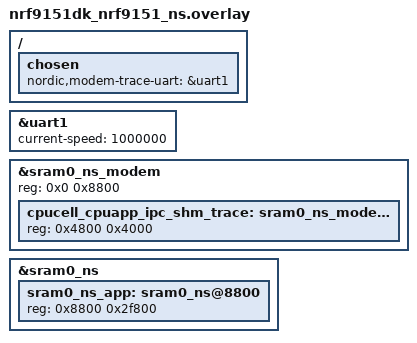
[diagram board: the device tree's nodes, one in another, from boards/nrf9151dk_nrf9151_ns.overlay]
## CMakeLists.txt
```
#
# Copyright (c) 2023 Nordic Semiconductor
#
# SPDX-License-Identifier: LicenseRef-Nordic-5-Clause
#

cmake_minimum_required(VERSION 3.20.0)

find_package(Zephyr REQUIRED HINTS $ENV{ZEPHYR_BASE})
project(udp)

# NORDIC SDK APP START
target_sources(app PRIVATE src/main.c)
# NORDIC SDK APP END

zephyr_include_directories(src)
```

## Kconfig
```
#
# Copyright (c) 2023 Nordic Semiconductor ASA
#
# SPDX-License-Identifier: LicenseRef-Nordic-5-Clause
#

menu "UDP sample settings"

config UDP_SAMPLE_DATA_UPLOAD_SIZE_BYTES
	int "Number of bytes transmitted to the server"
	default 10

config UDP_SAMPLE_DATA_UPLOAD_FREQUENCY_SECONDS
	int "How often data is transmitted to the server"
	default 900

config UDP_SAMPLE_SERVER_ADDRESS_STATIC
	string "UDP server IP address"
	default "8.8.8.8"

config UDP_SAMPLE_SERVER_PORT
	int "UDP server port number"
	default "2469"

endmenu

module = UDP_SAMPLE
module-str = UDP sample
source "$(ZEPHYR_BASE)/subsys/logging/Kconfig.template.log_config"

menu "Zephyr Kernel"
source "Kconfig.zephyr"
endmenu
```

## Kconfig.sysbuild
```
#
# Copyright (c) 2024 Nordic Semiconductor ASA
#
# SPDX-License-Identifier: LicenseRef-Nordic-5-Clause
#

config WIFI_NRF70
	default y if BOARD_NRF7002DK_NRF5340_CPUAPP_NS || \
		BOARD_NRF5340DK_NRF5340_CPUAPP_NS || \
		BOARD_NRF54L15DK_NRF54L15_CPUAPP || \
		BOARD_NRF54H20DK_NRF54H20_CPUAPP || \
		BOARD_NRF54LM20DK_NRF54LM20A_CPUAPP || \
		BOARD_NRF54LM20DK_NRF54LM20B_CPUAPP

config PARTITION_MANAGER
	default n

source "share/sysbuild/Kconfig"
```

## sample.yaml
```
sample:
  name: UDP sample
tests:
  sample.net.udp:
    sysbuild: true
    build_only: true
    integration_platforms:
      - nrf9151dk/nrf9151/ns
    platform_allow:
      - nrf9151dk/nrf9151/ns
    tags:
      - ci_build
      - sysbuild
      - ci_samples_net
  sample.net.udp.emulation:
    sysbuild: true
    build_only: true
    integration_platforms:
      - native_sim
    platform_allow:
      - native_sim
    tags:
      - ci_build
      - sysbuild
      - ci_samples_net
  sample.net.udp.wifi:
    sysbuild: true
    build_only: true
    integration_platforms:
      - nrf7002dk/nrf5340/cpuapp/ns
      - nrf7120dk/nrf7120/cpuapp/ns
    platform_allow:
      - nrf7002dk/nrf5340/cpuapp/ns
      - nrf7120dk/nrf7120/cpuapp/ns
    tags:
      - ci_build
      - sysbuild
      - ci_samples_net
    extra_args:
      - udp_EXTRA_CONF_FILE="wifi.conf"
  sample.net.udp.nrf7002eb_interposer.wifi:
    sysbuild: true
    build_only: true
    integration_platforms:
      - nrf54h20dk/nrf54h20/cpuapp
    platform_allow:
      - nrf54h20dk/nrf54h20/cpuapp
    tags:
      - ci_build
      - sysbuild
      - ci_samples_net
    extra_args:
      - udp_SHIELD="nrf7002eb_interposer_p1;nrf7002eb"
      - udp_SNIPPET="nrf70-wifi;wifi-credentials"
      - udp_EXTRA_CONF_FILE="wifi.conf"
  sample.net.udp.nrf54l15_nrf7002eb2.wifi:
    sysbuild: true
    build_only: true
    integration_platforms:
      - nrf54l15dk/nrf54l15/cpuapp
    platform_allow:
      - nrf54l15dk/nrf54l15/cpuapp
    tags:
      - ci_build
      - sysbuild
      - ci_samples_net
    extra_args:
      - udp_SHIELD="nrf7002eb2"
      - udp_SNIPPET="nrf70-wifi;wifi-credentials"
      - udp_EXTRA_CONF_FILE="wifi.conf"
  sample.net.udp.nrf54lm20_nrf7002eb2.wifi:
    sysbuild: true
    build_only: true
    integration_platforms:
      - nrf54lm20dk/nrf54lm20a/cpuapp
      - nrf54lm20dk/nrf54lm20b/cpuapp
    platform_allow:
      - nrf54lm20dk/nrf54lm20a/cpuapp
      - nrf54lm20dk/nrf54lm20b/cpuapp
    tags:
      - ci_build
      - sysbuild
      - ci_samples_net
    extra_args:
      - udp_SHIELD="nrf7002eb2"
      - udp_SNIPPET=wifi-credentials
      - udp_EXTRA_CONF_FILE="wifi.conf"
```

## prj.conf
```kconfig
#
# Copyright (c) 2023 Nordic Semiconductor ASA
#
# SPDX-License-Identifier: LicenseRef-Nordic-5-Clause
#

# General configurations
CONFIG_LOG=y

# Network
CONFIG_NETWORKING=y
CONFIG_NET_NATIVE=y
CONFIG_NET_IPV4=y
CONFIG_NET_IPV6=y
CONFIG_NET_SOCKETS=y
CONFIG_POSIX_API=y
CONFIG_NET_CONNECTION_MANAGER=y

# Heap and stacks
CONFIG_HEAP_MEM_POOL_SIZE=1280
CONFIG_MAIN_STACK_SIZE=4096
CONFIG_SYSTEM_WORKQUEUE_STACK_SIZE=2048
```

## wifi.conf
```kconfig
#
# Copyright (c) 2026 Nordic Semiconductor ASA
#
# SPDX-License-Identifier: LicenseRef-Nordic-5-Clause
#

# Common Wi-Fi + networking configuration shared by all Wi-Fi builds of
# this sample (nRF70 and nRF71).

# Logging
CONFIG_NET_LOG=y

# Wi-Fi stack
CONFIG_WIFI=y
CONFIG_WIFI_NM_WPA_SUPPLICANT=y
CONFIG_WIFI_NM_WPA_SUPPLICANT_LOG_LEVEL_INF=y
CONFIG_NET_L2_ETHERNET=y

# Wi-Fi credentials. TF-M (_ns) builds use PSA Protected Storage. Non-TF-M
# builds use the Settings subsystem, requiring the wifi-credentials snippet.
CONFIG_WIFI_CREDENTIALS=y

# Connection Manager Wi-Fi connectivity layer (sdk-nrf).
CONFIG_L2_WIFI_CONNECTIVITY=y
CONFIG_L2_WIFI_CONNECTIVITY_AUTO_CONNECT=n
CONFIG_L2_WIFI_CONNECTIVITY_AUTO_DOWN=n

# Networking
CONFIG_NET_SOCKETS=y
CONFIG_NET_SOCKETS_OFFLOAD=n
CONFIG_NET_IPV6=y
CONFIG_NET_UDP=y
CONFIG_NET_TCP=y
CONFIG_NET_DHCPV4=y
# Run DHCPv6 on RA, covering both stateful and stateless configurations
CONFIG_NET_DHCPV6=y
CONFIG_NET_DHCPV6_START_ON_RA=y
CONFIG_NET_CONTEXT_SNDTIMEO=y
CONFIG_NET_CONTEXT_RCVTIMEO=y

# DNS
CONFIG_DNS_RESOLVER=y
CONFIG_NET_SOCKETS_DNS_TIMEOUT=30000

# Wi-Fi shell
CONFIG_SHELL=y
CONFIG_SHELL_CMDS_RESIZE=n
CONFIG_NET_L2_WIFI_SHELL=y

# POSIX
CONFIG_POSIX_NETWORKING=y
CONFIG_POSIX_FD_MGMT=n
CONFIG_POSIX_MESSAGE_PASSING=n
CONFIG_POSIX_THREAD_THREADS_MAX=0

# Network resource sizing (workload-specific for this sample)
CONFIG_NET_MAX_CONN=8
CONFIG_NET_MAX_CONTEXTS=6
CONFIG_ZVFS_POLL_MAX=8
CONFIG_NET_PKT_TX_COUNT=6
CONFIG_NET_PKT_RX_COUNT=6
CONFIG_NET_BUF_TX_COUNT=12
CONFIG_NET_BUF_RX_COUNT=6
CONFIG_NET_PKT_BUF_RX_DATA_POOL_SIZE=4096
CONFIG_NET_PKT_BUF_TX_DATA_POOL_SIZE=4096

# Floating-point printf support (Wi-Fi shell prints PHY TX rate as %f)
CONFIG_CBPRINTF_FP_SUPPORT=y

# Stack sizes
CONFIG_MAIN_STACK_SIZE=6144
CONFIG_SHELL_STACK_SIZE=6144
CONFIG_NET_RX_STACK_SIZE=4096

# Heap sizes
CONFIG_HEAP_MEM_POOL_IGNORE_MIN=y
CONFIG_HEAP_MEM_POOL_SIZE=37000
CONFIG_NRF_WIFI_DATA_HEAP_SIZE=65536
```

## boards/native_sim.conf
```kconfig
#
# Copyright (c) 2023 Nordic Semiconductor ASA
#
# SPDX-License-Identifier: LicenseRef-Nordic-5-Clause
#

# Networking config
CONFIG_NET_TCP=y
CONFIG_NET_UDP=y
CONFIG_NET_SOCKETS=y
CONFIG_POSIX_API=y
CONFIG_MBEDTLS_CIPHERSUITE_TLS_ECDHE_RSA_WITH_AES_128_CBC_SHA256=y
CONFIG_NET_SOCKETS_SOCKOPT_TLS=y
CONFIG_NET_PKT_RX_COUNT=32
CONFIG_NET_PKT_TX_COUNT=32
CONFIG_NET_BUF_RX_COUNT=32
CONFIG_NET_BUF_TX_COUNT=32
CONFIG_NET_IF_UNICAST_IPV6_ADDR_COUNT=3
CONFIG_NET_IF_MCAST_IPV6_ADDR_COUNT=4
CONFIG_NET_MAX_CONTEXTS=10
CONFIG_NET_L2_ETHERNET=y
CONFIG_NET_CONTEXT_SNDTIMEO=y

CONFIG_ETH_NATIVE_TAP=y

# Network driver config
CONFIG_TEST_RANDOM_GENERATOR=y

# DNS
CONFIG_DNS_RESOLVER=y
CONFIG_DNS_SERVER_IP_ADDRESSES=y
CONFIG_DNS_SERVER1="8.8.8.8"
CONFIG_DNS_RESOLVER_MAX_SERVERS=2

# Network address config
CONFIG_NET_CONFIG_SETTINGS=y
CONFIG_NET_CONFIG_NEED_IPV4=y
CONFIG_NET_CONFIG_MY_IPV4_ADDR="192.0.2.1"
CONFIG_NET_CONFIG_MY_IPV4_GW="192.0.2.2"
```

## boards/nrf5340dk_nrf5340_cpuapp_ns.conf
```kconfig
#
# Copyright (c) 2025 Nordic Semiconductor ASA
#
# SPDX-License-Identifier: LicenseRef-Nordic-5-Clause
#

# General
CONFIG_POSIX_TIMERS=y
CONFIG_HEAP_MEM_POOL_SIZE=40144
CONFIG_NRF_WIFI_CTRL_HEAP_SIZE=15000
CONFIG_NRF_WIFI_DATA_HEAP_SIZE=64856
CONFIG_HEAP_MEM_POOL_IGNORE_MIN=y
CONFIG_MAIN_STACK_SIZE=6144

# Wi-Fi
CONFIG_WIFI=y
CONFIG_WIFI_NRF70=y
CONFIG_WIFI_CREDENTIALS=y

# Optimize Wi-Fi stack to save some memory
CONFIG_NRF70_RX_NUM_BUFS=16
CONFIG_NRF70_MAX_TX_AGGREGATION=4

# Shell
CONFIG_SHELL=y
CONFIG_SHELL_STACK_SIZE=6144
CONFIG_NET_L2_WIFI_SHELL=y

# WPA
CONFIG_WIFI_NM_WPA_SUPPLICANT=y

# NET sockets
CONFIG_NET_L2_ETHERNET=y
CONFIG_NET_UDP=y
CONFIG_NET_DHCPV4=y

# DNS
CONFIG_DNS_RESOLVER=y
CONFIG_NET_SOCKETS_DNS_TIMEOUT=30000

# Zephyr NET Connection Manager Connectivity layer.
CONFIG_L2_WIFI_CONNECTIVITY=y
CONFIG_L2_WIFI_CONNECTIVITY_AUTO_CONNECT=n
CONFIG_L2_WIFI_CONNECTIVITY_AUTO_DOWN=n

# Optimize TF-M
CONFIG_TFM_PROFILE_TYPE_SMALL=y

# Floating-point printf support
CONFIG_CBPRINTF_FP_SUPPORT=y
```

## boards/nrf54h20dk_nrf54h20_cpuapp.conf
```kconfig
#
# Copyright (c) 2024 Nordic Semiconductor ASA
#
# SPDX-License-Identifier: LicenseRef-Nordic-5-Clause
#

# Logging
CONFIG_LOG=y
CONFIG_LOG_MODE_IMMEDIATE=y

# Wi-Fi
CONFIG_WIFI=y
CONFIG_WIFI_NRF70=y
CONFIG_WIFI_CREDENTIALS=y
# Needed for Wi-Fi credentials
CONFIG_FLASH=y
CONFIG_FLASH_PAGE_LAYOUT=y
CONFIG_FLASH_MAP=y
CONFIG_ZMS=y
CONFIG_SETTINGS=y

# WPA supplicant
CONFIG_WIFI_NM_WPA_SUPPLICANT=y
CONFIG_WIFI_NM_WPA_SUPPLICANT_LOG_LEVEL_INF=y

# Networking
CONFIG_NET_L2_ETHERNET=y
CONFIG_NET_SOCKETS=y
CONFIG_NET_IPV6=y
CONFIG_NET_UDP=y
CONFIG_NET_TCP=y
CONFIG_NET_DHCPV4=y
CONFIG_DNS_RESOLVER=y
CONFIG_DNS_RESOLVER_AI_MAX_ENTRIES=4

# NET sockets
CONFIG_NET_UDP=y
CONFIG_NET_TCP=y
CONFIG_NET_MAX_CONN=6
CONFIG_NET_MAX_CONTEXTS=5
CONFIG_ZVFS_POLL_MAX=8
CONFIG_NET_SOCKETS_OFFLOAD=n
CONFIG_NET_DHCPV4=y
CONFIG_NET_CONTEXT_SNDTIMEO=y
CONFIG_NET_CONTEXT_RCVTIMEO=y
CONFIG_NET_MAX_CONTEXTS=3

# NET buffers
CONFIG_NET_PKT_TX_COUNT=6
CONFIG_NET_PKT_RX_COUNT=6
CONFIG_NET_BUF_TX_COUNT=12
CONFIG_NET_BUF_RX_COUNT=6
CONFIG_NRF70_RX_NUM_BUFS=6
CONFIG_NET_PKT_BUF_RX_DATA_POOL_SIZE=4096
CONFIG_NET_PKT_BUF_TX_DATA_POOL_SIZE=4096
CONFIG_NRF70_MAX_TX_AGGREGATION=1

# Kernel options
CONFIG_POSIX_NETWORKING=y
CONFIG_ZVFS_OPEN_MAX=21

# Shell
CONFIG_SHELL=y
CONFIG_SHELL_CMDS_RESIZE=n
CONFIG_NET_L2_WIFI_SHELL=y

# Zephyr NET Connection Manager Connectivity layer.
CONFIG_L2_WIFI_CONNECTIVITY=y
CONFIG_L2_WIFI_CONNECTIVITY_AUTO_CONNECT=y
CONFIG_L2_WIFI_CONNECTIVITY_AUTO_DOWN=n

# Stack sizes
CONFIG_MAIN_STACK_SIZE=6144
CONFIG_NET_TX_STACK_SIZE=2048
CONFIG_NET_RX_STACK_SIZE=2048
CONFIG_NET_MGMT_EVENT_STACK_SIZE=4096
CONFIG_SYSTEM_WORKQUEUE_STACK_SIZE=3100
CONFIG_NRF70_IRQ_WQ_STACK_SIZE=1024
CONFIG_NRF70_BH_WQ_STACK_SIZE=2300
CONFIG_SHELL_STACK_SIZE=4400
CONFIG_ISR_STACK_SIZE=512

# Heap sizes
CONFIG_HEAP_MEM_POOL_IGNORE_MIN=y
CONFIG_HEAP_MEM_POOL_SIZE=32000
CONFIG_NRF_WIFI_CTRL_HEAP_SIZE=15000
CONFIG_NRF_WIFI_DATA_HEAP_SIZE=40000
# POSIX API memory optimizations
CONFIG_POSIX_FD_MGMT=n
CONFIG_POSIX_MESSAGE_PASSING=n
CONFIG_POSIX_THREAD_THREADS_MAX=0

# Floating-point printf support
CONFIG_CBPRINTF_FP_SUPPORT=y
```

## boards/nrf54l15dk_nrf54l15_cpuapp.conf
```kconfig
#
# Copyright (c) 2024 Nordic Semiconductor ASA
#
# SPDX-License-Identifier: LicenseRef-Nordic-5-Clause
#

# Logging
CONFIG_LOG=y
CONFIG_LOG_MODE_IMMEDIATE=y

# Wi-Fi
CONFIG_WIFI=y
CONFIG_WIFI_NRF70=y
CONFIG_WIFI_CREDENTIALS=y
# Needed for Wi-Fi credentials
CONFIG_FLASH=y
CONFIG_FLASH_PAGE_LAYOUT=y
CONFIG_FLASH_MAP=y
CONFIG_ZMS=y
CONFIG_SETTINGS=y

# WPA supplicant
CONFIG_WIFI_NM_WPA_SUPPLICANT=y
CONFIG_WIFI_NM_WPA_SUPPLICANT_LOG_LEVEL_INF=y

# Networking
CONFIG_NET_L2_ETHERNET=y
CONFIG_NET_SOCKETS=y
CONFIG_NET_IPV6=y
CONFIG_NET_UDP=y
CONFIG_NET_TCP=y
CONFIG_NET_DHCPV4=y
CONFIG_DNS_RESOLVER=y
CONFIG_DNS_RESOLVER_AI_MAX_ENTRIES=4

# NET sockets
CONFIG_NET_UDP=y
CONFIG_NET_TCP=y
CONFIG_NET_MAX_CONN=6
CONFIG_NET_MAX_CONTEXTS=5
CONFIG_ZVFS_POLL_MAX=8
CONFIG_NET_SOCKETS_OFFLOAD=n
CONFIG_NET_DHCPV4=y
CONFIG_NET_CONTEXT_SNDTIMEO=y
CONFIG_NET_CONTEXT_RCVTIMEO=y
CONFIG_NET_MAX_CONTEXTS=3

# NET buffers
CONFIG_NET_PKT_TX_COUNT=6
CONFIG_NET_PKT_RX_COUNT=6
CONFIG_NET_BUF_TX_COUNT=12
CONFIG_NET_BUF_RX_COUNT=6
CONFIG_NRF70_RX_NUM_BUFS=6
CONFIG_NET_PKT_BUF_RX_DATA_POOL_SIZE=4096
CONFIG_NET_PKT_BUF_TX_DATA_POOL_SIZE=4096
CONFIG_NRF70_MAX_TX_AGGREGATION=1

# Kernel options
CONFIG_POSIX_NETWORKING=y

# Shell
CONFIG_SHELL=y
CONFIG_SHELL_CMDS_RESIZE=n
CONFIG_NET_L2_WIFI_SHELL=y

# Zephyr NET Connection Manager Connectivity layer.
CONFIG_L2_WIFI_CONNECTIVITY=y
CONFIG_L2_WIFI_CONNECTIVITY_AUTO_CONNECT=y
CONFIG_L2_WIFI_CONNECTIVITY_AUTO_DOWN=n

# Stack sizes
CONFIG_MAIN_STACK_SIZE=6144
CONFIG_NET_TX_STACK_SIZE=2048
CONFIG_NET_RX_STACK_SIZE=2048
CONFIG_NET_MGMT_EVENT_STACK_SIZE=4096
CONFIG_SYSTEM_WORKQUEUE_STACK_SIZE=3100
CONFIG_NRF70_IRQ_WQ_STACK_SIZE=1024
CONFIG_NRF70_BH_WQ_STACK_SIZE=2300
CONFIG_SHELL_STACK_SIZE=4400
CONFIG_ISR_STACK_SIZE=512

# Heap sizes
CONFIG_HEAP_MEM_POOL_IGNORE_MIN=y
CONFIG_HEAP_MEM_POOL_SIZE=32000
CONFIG_NRF_WIFI_CTRL_HEAP_SIZE=15000
CONFIG_NRF_WIFI_DATA_HEAP_SIZE=40000
# POSIX API memory optimizations
CONFIG_POSIX_FD_MGMT=n
CONFIG_POSIX_MESSAGE_PASSING=n
CONFIG_POSIX_THREAD_THREADS_MAX=0

# Floating-point printf support
CONFIG_CBPRINTF_FP_SUPPORT=y
```

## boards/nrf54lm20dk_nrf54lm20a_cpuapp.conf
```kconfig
#
# Copyright (c) 2025 Nordic Semiconductor ASA
#
# SPDX-License-Identifier: LicenseRef-Nordic-5-Clause
#

# Logging
CONFIG_LOG=y
CONFIG_LOG_MODE_IMMEDIATE=y

# Wi-Fi
CONFIG_WIFI=y
CONFIG_WIFI_NRF70=y
CONFIG_WIFI_CREDENTIALS=y
# Needed for Wi-Fi credentials
CONFIG_FLASH=y
CONFIG_FLASH_PAGE_LAYOUT=y
CONFIG_FLASH_MAP=y
CONFIG_ZMS=y
CONFIG_SETTINGS=y

# WPA supplicant
CONFIG_WIFI_NM_WPA_SUPPLICANT=y
CONFIG_WIFI_NM_WPA_SUPPLICANT_LOG_LEVEL_INF=y

# Networking
CONFIG_NET_L2_ETHERNET=y
CONFIG_NET_SOCKETS=y
CONFIG_NET_IPV6=y
CONFIG_NET_UDP=y
CONFIG_NET_TCP=y
CONFIG_NET_DHCPV4=y
CONFIG_DNS_RESOLVER=y
CONFIG_DNS_RESOLVER_AI_MAX_ENTRIES=4

# NET sockets
CONFIG_NET_UDP=y
CONFIG_NET_TCP=y
CONFIG_NET_MAX_CONN=6
CONFIG_NET_MAX_CONTEXTS=5
CONFIG_ZVFS_POLL_MAX=8
CONFIG_NET_SOCKETS_OFFLOAD=n
CONFIG_NET_DHCPV4=y
CONFIG_NET_CONTEXT_SNDTIMEO=y
CONFIG_NET_CONTEXT_RCVTIMEO=y
CONFIG_NET_MAX_CONTEXTS=3

# NET buffers
CONFIG_NET_PKT_TX_COUNT=6
CONFIG_NET_PKT_RX_COUNT=6
CONFIG_NET_BUF_TX_COUNT=12
CONFIG_NET_BUF_RX_COUNT=6
CONFIG_NRF70_RX_NUM_BUFS=6
CONFIG_NET_PKT_BUF_RX_DATA_POOL_SIZE=4096
CONFIG_NET_PKT_BUF_TX_DATA_POOL_SIZE=4096
CONFIG_NRF70_MAX_TX_AGGREGATION=1

# Kernel options
CONFIG_POSIX_NETWORKING=y
CONFIG_ZVFS_OPEN_MAX=21

# Shell
CONFIG_SHELL=y
CONFIG_SHELL_CMDS_RESIZE=n
CONFIG_NET_L2_WIFI_SHELL=y

# Zephyr NET Connection Manager Connectivity layer.
CONFIG_L2_WIFI_CONNECTIVITY=y
CONFIG_L2_WIFI_CONNECTIVITY_AUTO_CONNECT=y
CONFIG_L2_WIFI_CONNECTIVITY_AUTO_DOWN=n

# Stack sizes
CONFIG_NET_CONNECTION_MANAGER_MONITOR_STACK_SIZE=5000
CONFIG_MAIN_STACK_SIZE=6144
CONFIG_NET_TX_STACK_SIZE=2048
CONFIG_NET_RX_STACK_SIZE=2048
CONFIG_NET_MGMT_EVENT_STACK_SIZE=4096
CONFIG_SYSTEM_WORKQUEUE_STACK_SIZE=3100
CONFIG_NRF70_IRQ_WQ_STACK_SIZE=1024
CONFIG_NRF70_BH_WQ_STACK_SIZE=2300
CONFIG_SHELL_STACK_SIZE=4800
CONFIG_ISR_STACK_SIZE=512

# Heap sizes
CONFIG_HEAP_MEM_POOL_IGNORE_MIN=y
CONFIG_HEAP_MEM_POOL_SIZE=32000
CONFIG_NRF_WIFI_CTRL_HEAP_SIZE=15000
CONFIG_NRF_WIFI_DATA_HEAP_SIZE=40000
# POSIX API memory optimizations
CONFIG_POSIX_FD_MGMT=n
CONFIG_POSIX_MESSAGE_PASSING=n
CONFIG_POSIX_THREAD_THREADS_MAX=0
```

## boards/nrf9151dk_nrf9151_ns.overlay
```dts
/*
 * Copyright (c) 2024 Nordic Semiconductor ASA
 *
 * SPDX-License-Identifier: LicenseRef-Nordic-5-Clause
 */

#include <samples/cellular/nrf91_no_bootloader_partitions.dtsi>

#include <samples/cellular/nrf91_sram_partitions.dtsi>

/* Enable uart1 for tracing. */
&uart1 {
	status = "okay";
	current-speed = <1000000>;
};

/ {
	chosen {
		nordic,modem-trace-uart = &uart1;
	};
};

/* Increase modem (shared) memory and add trace partition. */
&sram0_ns_modem {
	reg = <0x0 0x8800>;
	ranges = <0x0 0x0 0x8800>;

	cpucell_cpuapp_ipc_shm_trace: sram0_ns_modem@4800 {
		/* Modem trace memory */
		reg = <0x4800 0x4000>;
	};
};

/* Delete Non-Secure application memory so we can move and shrink it. */
/delete-node/ &sram0_ns_app;

&sram0_ns {
	sram0_ns_app: sram0_ns@8800 {
		/* Redefine smaller Non-Secure application memory. */
		reg = <0x8800 0x2f800>;
	};
};
```

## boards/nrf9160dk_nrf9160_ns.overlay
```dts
/*
 * Copyright (c) 2023 Nordic Semiconductor ASA
 *
 * SPDX-License-Identifier: LicenseRef-Nordic-5-Clause
 */

#include <samples/cellular/nrf91_no_bootloader_partitions.dtsi>

#include <samples/cellular/nrf91_sram_partitions.dtsi>

/* Enable uart1 for tracing. */
&uart1 {
	status = "okay";
	current-speed = <1000000>;
};

/ {
	chosen {
		nordic,modem-trace-uart = &uart1;
	};
};

/* Increase modem (shared) memory and add trace partition. */
&sram0_ns_modem {
	reg = <0x0 0x8800>;
	ranges = <0x0 0x0 0x8800>;

	cpucell_cpuapp_ipc_shm_trace: sram0_ns_modem@4800 {
		/* Modem trace memory */
		reg = <0x4800 0x4000>;
	};
};

/* Delete Non-Secure application memory so we can move and shrink it. */
/delete-node/ &sram0_ns_app;

&sram0_ns {
	sram0_ns_app: sram0_ns@8800 {
		/* Redefine smaller Non-Secure application memory. */
		reg = <0x8800 0x2f800>;
	};
};
```

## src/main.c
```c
/*
 * Copyright (c) 2023 Nordic Semiconductor ASA
 *
 * SPDX-License-Identifier: LicenseRef-Nordic-5-Clause
 */

#include <stdbool.h>
#include <stdio.h>
#include <string.h>
#include <zephyr/kernel.h>
#include <zephyr/logging/log.h>
#include <zephyr/logging/log_ctrl.h>
#include <zephyr/sys/reboot.h>
#include <zephyr/net/socket.h>
#include <zephyr/net/net_ip.h>
#include <zephyr/net/conn_mgr_connectivity.h>

#if defined(CONFIG_POSIX_API)
#include <zephyr/posix/arpa/inet.h>
#include <zephyr/posix/unistd.h>
#include <zephyr/posix/sys/socket.h>
#endif

LOG_MODULE_REGISTER(udp_sample, CONFIG_UDP_SAMPLE_LOG_LEVEL);

#define UDP_IP_HEADER_SIZE_IPV4 28
#define UDP_IP_HEADER_SIZE_IPV6 48

/* Macros used to subscribe to specific Zephyr NET management events. */
#define L4_EVENT_MASK (NET_EVENT_L4_IPV4_CONNECTED | NET_EVENT_L4_IPV4_DISCONNECTED | \
		       NET_EVENT_L4_IPV6_CONNECTED | NET_EVENT_L4_IPV6_DISCONNECTED)
#define CONN_LAYER_EVENT_MASK (NET_EVENT_CONN_IF_FATAL_ERROR)

/* Macro called upon a fatal error, reboots the device. */
#define FATAL_ERROR()					\
	LOG_ERR("Fatal error! Rebooting the device.");	\
	LOG_PANIC();					\
	IF_ENABLED(CONFIG_REBOOT, (sys_reboot(0)))

/* Variables used to perform socket operations. */
static int fd;
static struct sockaddr_storage host_addr;
static sa_family_t host_addr_family;

/* Forward declarations */
static void server_transmission_work_fn(struct k_work *work);

/* Work item used to schedule periodic UDP transmissions. */
static K_WORK_DELAYABLE_DEFINE(server_transmission_work, server_transmission_work_fn);

static void server_transmission_work_fn(struct k_work *work)
{
	int err;
	char buffer[CONFIG_UDP_SAMPLE_DATA_UPLOAD_SIZE_BYTES] = {"\0"};
	const int ip_header_size = (host_addr_family == AF_INET6) ?
				    UDP_IP_HEADER_SIZE_IPV6 : UDP_IP_HEADER_SIZE_IPV4;

	LOG_INF("Transmitting UDP/IP payload of %d bytes to the "
		"IP address %s, port number %d",
		CONFIG_UDP_SAMPLE_DATA_UPLOAD_SIZE_BYTES + ip_header_size,
		CONFIG_UDP_SAMPLE_SERVER_ADDRESS_STATIC,
		CONFIG_UDP_SAMPLE_SERVER_PORT);

	err = send(fd, buffer, sizeof(buffer), 0);
	if (err < 0) {
		LOG_ERR("Failed to transmit UDP packet, %d", -errno);
		return;
	}

	(void)k_work_reschedule(&server_transmission_work,
				K_SECONDS(CONFIG_UDP_SAMPLE_DATA_UPLOAD_FREQUENCY_SECONDS));
}

/* Determine IP address family and construct the server address structure. */
static int server_addr_construct(void)
{
	bool ret;

	ret = net_ipaddr_parse(CONFIG_UDP_SAMPLE_SERVER_ADDRESS_STATIC,
				strlen(CONFIG_UDP_SAMPLE_SERVER_ADDRESS_STATIC),
				(struct sockaddr *)&host_addr);
	if (!ret) {
		LOG_ERR("net_ipaddr_parse, failed to parse %s",
			CONFIG_UDP_SAMPLE_SERVER_ADDRESS_STATIC);
		return -EINVAL;
	}

	host_addr_family = ((struct sockaddr *)&host_addr)->sa_family;

	if (host_addr_family == AF_INET6) {
		struct sockaddr_in6 *server6 = ((struct sockaddr_in6 *)&host_addr);

		if (server6->sin6_port == 0) {
			server6->sin6_port = htons(CONFIG_UDP_SAMPLE_SERVER_PORT);
		}
	} else {
		struct sockaddr_in *server4 = ((struct sockaddr_in *)&host_addr);

		if (server4->sin_port == 0) {
			server4->sin_port = htons(CONFIG_UDP_SAMPLE_SERVER_PORT);
		}
	}

	return 0;
}

static void on_net_event_l4_connected(void)
{
	int err;

	socklen_t addr_len = (host_addr_family == AF_INET6) ?
				sizeof(struct sockaddr_in6) : sizeof(struct sockaddr_in);

	fd = socket(host_addr_family, SOCK_DGRAM, IPPROTO_UDP);
	if (fd < 0) {
		LOG_ERR("Failed to create UDP socket: %d", -errno);
		FATAL_ERROR();
		return;
	}

	err = connect(fd, (struct sockaddr *)&host_addr, addr_len);
	if (err < 0) {
		LOG_ERR("connect, error: %d", -errno);
		FATAL_ERROR();
		return;
	}

	(void)k_work_reschedule(&server_transmission_work, K_NO_WAIT);
}

static void on_net_event_l4_disconnected(void)
{
	(void)close(fd);
	(void)k_work_cancel_delayable(&server_transmission_work);
}

static void l4_event_handler(uint64_t event, struct net_if *iface, void *info,
			     size_t info_length, void *user_data)
{
	bool ipv6_event = (event == NET_EVENT_L4_IPV6_CONNECTED) ||
			  (event == NET_EVENT_L4_IPV6_DISCONNECTED);

	/* Parse server address */
	if (host_addr_family == AF_UNSPEC && server_addr_construct()) {
		LOG_ERR("server_addr_construct failed");
		FATAL_ERROR();
		return;
	}

	/* Only track the address family of the server */
	if (ipv6_event != (host_addr_family == AF_INET6)) {
		return;
	}

	switch (event) {
	case NET_EVENT_L4_IPV4_CONNECTED:
	case NET_EVENT_L4_IPV6_CONNECTED:
		LOG_INF("Network connectivity established");
		on_net_event_l4_connected();
		break;
	case NET_EVENT_L4_IPV4_DISCONNECTED:
	case NET_EVENT_L4_IPV6_DISCONNECTED:
		LOG_INF("Network connectivity lost");
		on_net_event_l4_disconnected();
		break;
	default:
		/* Don't care */
		return;
	}
}

static void connectivity_event_handler(uint64_t event, struct net_if *iface, void *info,
				       size_t info_length, void *user_data)
{
	if (event == NET_EVENT_CONN_IF_FATAL_ERROR) {
		LOG_ERR("NET_EVENT_CONN_IF_FATAL_ERROR");
		FATAL_ERROR();
		return;
	}
}

/* Registered statically to not miss events raised before main() */
NET_MGMT_REGISTER_EVENT_HANDLER(l4_events, L4_EVENT_MASK, l4_event_handler, NULL);
NET_MGMT_REGISTER_EVENT_HANDLER(conn_events, CONN_LAYER_EVENT_MASK, connectivity_event_handler,
				NULL);

int main(void)
{
	int err;

	LOG_INF("UDP sample has started");

	/* Connecting to the configured connectivity layer.
	 * Wi-Fi or LTE depending on the board that the sample was built for.
	 */
	LOG_INF("Bringing network interface up and connecting to the network");

	err = conn_mgr_all_if_up(true);
	if (err) {
		LOG_ERR("conn_mgr_all_if_up, error: %d", err);
		FATAL_ERROR();
		return err;
	}

	err = conn_mgr_all_if_connect(true);
	if (err) {
		LOG_ERR("conn_mgr_all_if_connect, error: %d", err);
		FATAL_ERROR();
		return err;
	}

	return 0;
}
```
